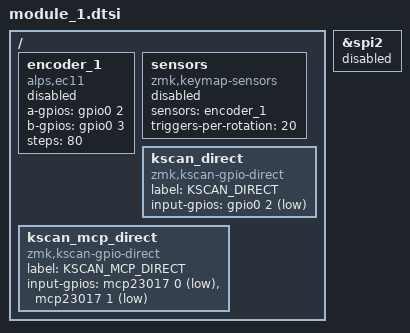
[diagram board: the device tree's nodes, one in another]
#include <dt-bindings/zmk/matrix_transform.h>
#include <dt-bindings/zmk/keys.h>
#include <dt-bindings/zmk/mouse.h>
#include <dt-bindings/gpio/gpio.h>
#include <zephyr/dt-bindings/input/input-event-codes.h>
// pinctrl.dtsi is included in the overlays

/ {
    // Temporarily disabled to avoid conflict with life_check on D0
    encoder_1: encoder_1 {
        compatible = "alps,ec11";
        a-gpios = <&gpio0 2 (GPIO_ACTIVE_HIGH | GPIO_PULL_UP)>;
        b-gpios = <&gpio0 3 (GPIO_ACTIVE_HIGH | GPIO_PULL_UP)>;
        steps = <80>;
        status = "disabled";
    };

    sensors: sensors {
        compatible = "zmk,keymap-sensors";
        sensors = <&encoder_1>;
        triggers-per-rotation = <20>;
        status = "disabled";
    };

    /* Commented out module_keys to resolve conflict with kscan_direct on D0
    module_keys {
        compatible = "gpio-keys";
        enc_switch: enc_switch {
            gpios = <&gpio0 1 (GPIO_ACTIVE_LOW | GPIO_PULL_UP)>;    
            label = "Encoder Switch";
            zephyr,code = <30>; // KEY_A (30)
        };
        life_check: life_check {
            gpios = <&gpio0 2 (GPIO_ACTIVE_LOW | GPIO_PULL_UP)>;
            label = "Life Check";
            zephyr,code = <29>; // KEY_Z (29)
        };
    };
    */

    kscan_direct: kscan_direct {
        compatible = "zmk,kscan-gpio-direct";
        label = "KSCAN_DIRECT";
        input-gpios = <&gpio0 2 (GPIO_ACTIVE_LOW | GPIO_PULL_UP)>; // D0
    };

    kscan_mcp_direct: kscan_mcp_direct {
        compatible = "zmk,kscan-gpio-direct";
        label = "KSCAN_MCP_DIRECT";
        input-gpios
            = <&mcp23017 0 (GPIO_ACTIVE_LOW | GPIO_PULL_UP)> // Pin 21
            , <&mcp23017 1 (GPIO_ACTIVE_LOW | GPIO_PULL_UP)> // Pin 22
            ;
    };

/* Temporarily disabled listener and SPI
    trackball_listener {
        compatible = "zmk,input-listener";
        device = <&trackball>;
    };
*/
};


&spi2 { status = "disabled"; };
